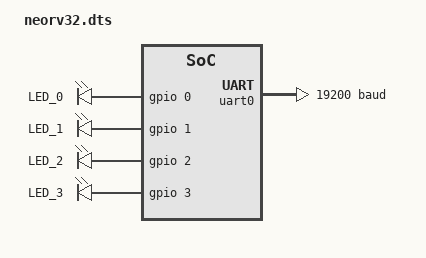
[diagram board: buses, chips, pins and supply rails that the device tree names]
/*
 * Copyright (c) 2021 Henrik Brix Andersen <henrik@brixandersen.dk>
 *
 * SPDX-License-Identifier: Apache-2.0
 */

/dts-v1/;

#include <neorv32.dtsi>
#include <freq.h>
#include <mem.h>

/ {
	aliases {
		led0 = &led0;
		led1 = &led1;
		led2 = &led2;
		led3 = &led3;
	};

	chosen {
		zephyr,flash = &imem;
		zephyr,sram = &dmem;
		zephyr,console = &uart0;
		zephyr,shell-uart = &uart0;
		zephyr,uart-pipe = &uart0;
	};

	soc {
		imem: memory@0 {
		//imem: memory@00020000 {
			compatible = "soc-nv-flash", "mmio-sram";
			reg = <0x0 DT_SIZE_K(64)>;
			// reg = <0xffff0000 DT_SIZE_K(128)>; /*(stevez) 10/5/2023 based on top.vhd (v1.8.6) from FPGA*/ 
		};

		// (stevez) original bootrom: memory@ffff0000
		bootrom: memory@ffff0000 {
			compatible = "soc-nv-flash", "mmio-sram";
			reg = <0xffff0000 DT_SIZE_K(4)>;
			// reg = <0xffff0000 DT_SIZE_K(32)>; /*(stevez) 10/5/2023 based on neorv32_package.vhd (v1.8.6)*/ 
		};

		dmem: memory@80000000 {
			compatible = "mmio-sram";
			reg = <0x80000000 DT_SIZE_K(32)>;
			// reg = <0xffff0000 DT_SIZE_K(64)>; /*(stevez) 10/5/2023 based on top.vhd (v1.8.6) from FPGA*/ 
		};
	};

	leds {
		compatible = "gpio-leds";
		led0: led0 {
			gpios = <&gpio 0 GPIO_ACTIVE_HIGH>;
			label = "LED_0";
		};

		led1: led1 {
			gpios = <&gpio 1 GPIO_ACTIVE_HIGH>;
			label = "LED_1";
		};

		led2: led2 {
			gpios = <&gpio 2 GPIO_ACTIVE_HIGH>;
			label = "LED_2";
		};

		led3: led3 {
			gpios = <&gpio 3 GPIO_ACTIVE_HIGH>;
			label = "LED_3";
		};
	};
};

&cpu0 {
	// clock-frequency = <DT_FREQ_M(100)>;
	// (stevez) same as Tera Term VT
		clock-frequency = <DT_FREQ_M(50)>;
};

&uart0 {
	status = "okay";
	current-speed = <19200>; 
};

&gpio_lo {
	status = "okay";
};

&gpio_hi {
	status = "okay";
};

